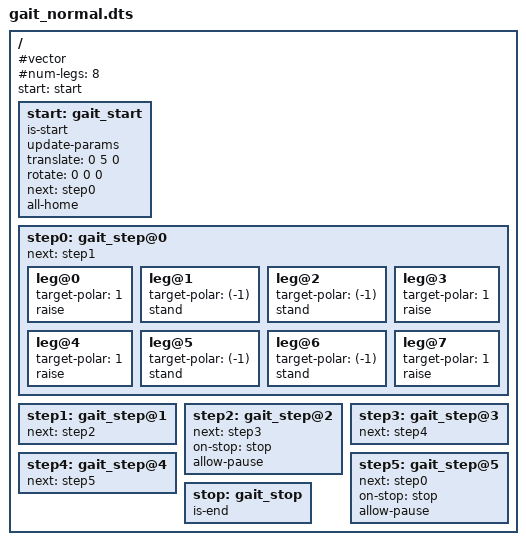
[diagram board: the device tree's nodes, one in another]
/dts-v1/;

/include/ "gait_common.dtsi"


/ {
    #vector;
    #num-legs = < 8 >;
    start = < &start >;

    start: gait_start {
        is-start;
        update-params;
        translate = < 0 5 0 >;
        rotate = < 0 0 0 >;
        next = < &step0 >;

        /*Home all legs*/
        all-home;

    };

    step0: gait_step@0 {
        next = < &step1 >;

        leg@0 {
            target-polar = < 1 >;
            raise; /*raise leg to target*/
        };
        leg@1 {
            target-polar = < (-1) >;
            stand; /*stand on leg (actually does nothing)*/
        };
        leg@2 {
            target-polar = < (-1) >;
            stand; /*raise leg to target*/
        };
        leg@3 {
            target-polar = < 1 >;
            raise; /*stand on leg (actually does nothing)*/
        };
        leg@4 {
            target-polar = < 1 >;
            raise; /*raise leg to target*/
        };
        leg@5 {
            target-polar = < (-1) >;
            stand; /*stand on leg (actually does nothing)*/
        };
        leg@6 {
            target-polar = < (-1) >;
            stand; /*raise leg to target*/
        };
        leg@7 {
            target-polar = < 1 >;
            raise; /*stand on leg (actually does nothing)*/
        };
    };

    step1: gait_step@1 {
        next = < &step2 >;
    };

    step2: gait_step@2 {
        next = < &step3 >;
        on-stop = < &stop >;
        allow-pause;
    };

    step3: gait_step@3 {
        next = < &step4 >;
    };

    step4: gait_step@4 {
        next = < &step5 >;
    };

    step5: gait_step@5 {
        next = < &step0 >;
        on-stop = < &stop >;
        allow-pause;
    };

    stop: gait_stop {
        is-end;
    };

};
